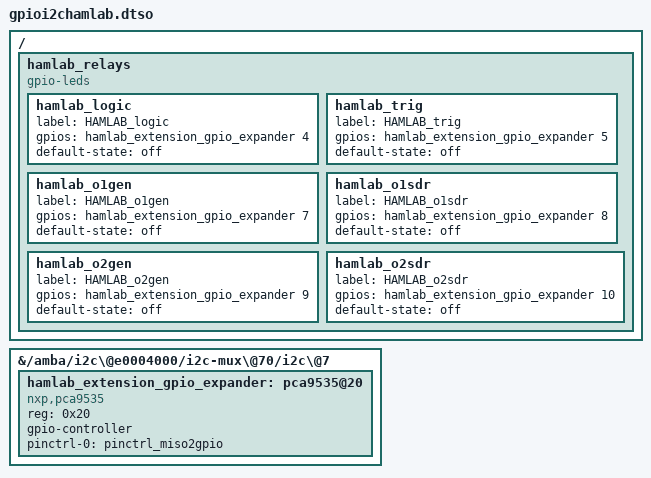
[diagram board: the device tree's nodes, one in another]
/*
 * HAMLAB specific features, mostly GPIO on I2C
 *
 * pca9555 I2C GPIO extender interrupt is connected
 * to MIO[10] used as GPIO, 0x2 specifies trigger mode:
 * 1 = low-to-high edge triggered
 * 2 = high-to-low edge triggered
 * 4 = high level triggered
 * 8 = low level triggered
 *
 * http://developer.toradex.com/knowledge-base/gpio-(linux)#GPIO_power_management_keys
*/

/dts-v1/;
/plugin/;

/ {
	fragment@20 {
		target-path = "/amba/i2c\@e0004000/i2c-mux\@70/i2c\@7";
		__overlay__ {
				hamlab_extension_gpio_expander: pca9535@20 {	
					compatible = "nxp,pca9535";
					reg = <0x20>;
					gpio-controller;
					#gpio-cells = <2>;
//					interrupt-parent = <&gpio0>;
//					interrupts = <11 0x2>;
//					interrupt-controller;
//					#interrupt-cells = <2>;
					pinctrl-names = "default";
					pinctrl-0 = <&pinctrl_miso2gpio>;
				};	
			};
		};

	/*fragment@22 {
		target-path = "/";
		__overlay__ {
			// DMM data ready is mapped as UIO interrupt connected to gpio_expander [15]
			dmm: dmm {
				compatible = "generic-uio";
				status = "okay";
				interrupt-parent = <&hamlab_extension_gpio_expander>;
				interrupts = <15 0x2>;
			};

			// Power button on MIO[11] (MISO)
			hamlab_keys {
				compatible = "gpio-keys";
				autorepeat;
				hamlab_key_power {
					label = "HAMLAB Key POWER";
					linux,code = <116>;
//					gpios = <&hamlab_extension_gpio_expander 14 1>;
					gpios = <&gpio0 11 1>;
				};
			};
			hamlab_led {
				compatible = "gpio-leds";
				hamlab_led_power {
					label = "HAMLAB LED POWER";
					gpios = <&hamlab_extension_gpio_expander 13 0>;
					default-state = "on";
				};
				hamlab_led_test0 {
					label = "HAMLAB LED test 0";
					gpios = <&hamlab_extension_gpio_expander 0 0>;
					default-state = "off";
				};
				hamlab_led_test1 {
					label = "HAMLAB LED test 1";
					gpios = <&hamlab_extension_gpio_expander 1 0>;
					default-state = "off";
				};
				hamlab_led_test2 {
					label = "HAMLAB LED test 2";
					gpios = <&hamlab_extension_gpio_expander 2 0>;
					default-state = "off";
				};
			};
		        // Power OFF signal, extension board GPIO expander port P16 (14=8+6)
			hamlab-poweroff {
				compatible = "gpio-poweroff";
				gpios = <&hamlab_extension_gpio_expander 12 0>;
			};
		};
	};*/
	
	fragment@23 {
		target-path = "/";
		__overlay__ {
			hamlab_relays {
				compatible = "gpio-leds";
				hamlab_logic {
					label = "HAMLAB_logic";
					gpios = <&hamlab_extension_gpio_expander 4 0>;
					default-state = "off";
				};
				
				hamlab_trig {
					label = "HAMLAB_trig";
					gpios = <&hamlab_extension_gpio_expander 5 0>;
					default-state = "off";
				};

				hamlab_o1gen {
					label = "HAMLAB_o1gen";
					gpios = <&hamlab_extension_gpio_expander 7 0>;
					default-state = "off";
				};				
				
				hamlab_o1sdr {
					label = "HAMLAB_o1sdr";
					gpios = <&hamlab_extension_gpio_expander 8 0>;
					default-state = "off";
				};
				hamlab_o2gen {
					label = "HAMLAB_o2gen";
					gpios = <&hamlab_extension_gpio_expander 9 0>;
					default-state = "off";
				};				
				
				hamlab_o2sdr {
					label = "HAMLAB_o2sdr";
					gpios = <&hamlab_extension_gpio_expander 10 0>;
					default-state = "off";
				};
			};
		};
	};
};
